# TOY1 register map
Vendor: Example; File version: 1.0
CPU: CM7, 4 interrupts
Registers are 32-bit, read-write, reset 0x5 unless marked. A register's access mark holds for its fields unless they carry their own. Offsets are from the block's base; lines under a group give offsets from that group; [hi:lo] are bit positions; {n}, {i} and the like mark numbered series; 'fields as' and 'values as' point back to an identical list; <NAME> marks a mode.

## Memory map
0x40001000 UARTA
0x40002000 UARTB

## Interrupts
2 UARTA_IRQ (UARTA, UARTB)
3 UARTB_IRQ (UARTB)

## UARTA
Base 0x40001000
Same registers: UARTB 0x40002000
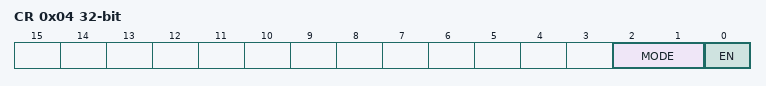
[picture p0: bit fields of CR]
0x04 CR
  [2:1] MODE
    0=OFF; 2=FAST
  [0] EN write-1-clears
0x04 CR_IN ro reset 0x0 (alternate view of CR)
  [15:8] LEVEL

## Licence text in the file
Copyright the vendor. SPDX-License-Identifier: Apache-2.0
